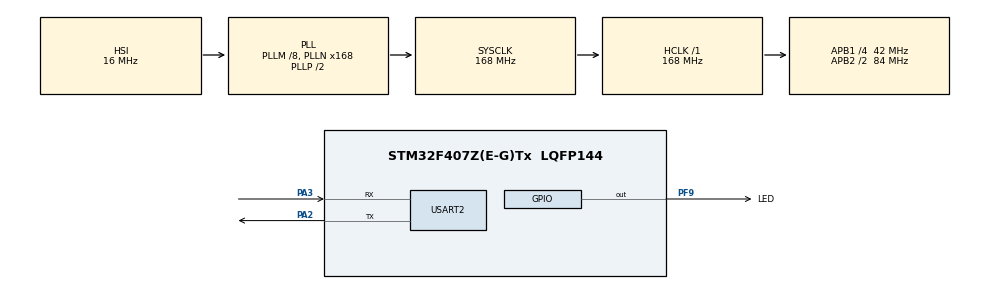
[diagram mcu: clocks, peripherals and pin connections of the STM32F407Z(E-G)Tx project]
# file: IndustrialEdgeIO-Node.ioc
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Dma.Request0=USART2_RX
Dma.Request1=USART2_TX
Dma.USART2_RX.0.Direction=DMA_PERIPH_TO_MEMORY
Dma.USART2_RX.0.FIFOMode=DMA_FIFOMODE_DISABLE
Dma.USART2_RX.0.Instance=DMA1_Stream5
Dma.USART2_RX.0.MemDataAlignment=DMA_MDATAALIGN_BYTE
Dma.USART2_RX.0.MemInc=DMA_MINC_ENABLE
Dma.USART2_RX.0.Mode=DMA_NORMAL
Dma.USART2_RX.0.PeriphDataAlignment=DMA_PDATAALIGN_BYTE
Dma.USART2_RX.0.PeriphInc=DMA_PINC_DISABLE
Dma.USART2_RX.0.Priority=DMA_PRIORITY_LOW
Dma.USART2_TX.1.Direction=DMA_MEMORY_TO_PERIPH
Dma.USART2_TX.1.FIFOMode=DMA_FIFOMODE_DISABLE
Dma.USART2_TX.1.Instance=DMA1_Stream6
Dma.USART2_TX.1.MemDataAlignment=DMA_MDATAALIGN_BYTE
Dma.USART2_TX.1.MemInc=DMA_MINC_ENABLE
Dma.USART2_TX.1.Mode=DMA_NORMAL
Dma.USART2_TX.1.PeriphDataAlignment=DMA_PDATAALIGN_BYTE
Dma.USART2_TX.1.PeriphInc=DMA_PINC_DISABLE
Dma.USART2_TX.1.Priority=DMA_PRIORITY_LOW
FREERTOS.Tasks01=defaultTask,24,128,StartDefaultTask,Default,NULL,Dynamic,NULL,NULL
Mcu.Family=STM32F4
Mcu.Name=STM32F407Z(E-G)Tx
Mcu.Package=LQFP144
NVIC.DMA1_Stream5_IRQn=true\:5\:0\:false\:false\:true\:true\:false\:true\:true
NVIC.DMA1_Stream6_IRQn=true\:5\:0\:false\:false\:true\:true\:false\:true\:true
NVIC.PriorityGroup=NVIC_PRIORITYGROUP_4
NVIC.TIM6_DAC_IRQn=true\:15\:0\:false\:false\:true\:false\:false\:true\:true
NVIC.TimeBase=TIM6_DAC_IRQn
NVIC.TimeBaseIP=TIM6
NVIC.USART2_IRQn=true\:5\:0\:false\:false\:true\:true\:true\:true\:true
PA13.Mode=Serial_Wire
PA13.Signal=SYS_JTMS-SWDIO
PA14.Mode=Serial_Wire
PA14.Signal=SYS_JTCK-SWCLK
PA2.Mode=Asynchronous
PA2.Signal=USART2_TX
PA3.Mode=Asynchronous
PA3.Signal=USART2_RX
PC14-OSC32_IN.Mode=LSE-External-Oscillator
PC14-OSC32_IN.Signal=RCC_OSC32_IN
PC15-OSC32_OUT.Mode=LSE-External-Oscillator
PC15-OSC32_OUT.Signal=RCC_OSC32_OUT
PF9.GPIO_Label=LED
PF9.Signal=GPIO_Output
PH0-OSC_IN.Mode=HSE-External-Oscillator
PH0-OSC_IN.Signal=RCC_OSC_IN
PH1-OSC_OUT.Mode=HSE-External-Oscillator
PH1-OSC_OUT.Signal=RCC_OSC_OUT
ProjectManager.HeapSize=0x200
ProjectManager.StackSize=0x400
ProjectManager.TargetToolchain=MDK-ARM V5.32
RCC.48MHZClocksFreq_Value=84000000
RCC.AHBFreq_Value=168000000
RCC.APB1CLKDivider=RCC_HCLK_DIV4
RCC.APB1Freq_Value=42000000
RCC.APB1TimFreq_Value=84000000
RCC.APB2CLKDivider=RCC_HCLK_DIV2
RCC.APB2Freq_Value=84000000
RCC.APB2TimFreq_Value=168000000
RCC.CortexFreq_Value=168000000
RCC.HCLKFreq_Value=168000000
RCC.HSE_VALUE=25000000
RCC.HSI_VALUE=16000000
RCC.PLLM=8
RCC.PLLN=168
RCC.SYSCLKFreq_VALUE=168000000
RCC.SYSCLKSource=RCC_SYSCLKSOURCE_PLLCLK
RCC.VCOOutputFreq_Value=336000000
USART2.VirtualMode=VM_ASYNC
VP_FREERTOS_VS_CMSIS_V2.Mode=CMSIS_V2
VP_SYS_VS_tim6.Mode=TIM6
board=custom

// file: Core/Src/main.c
/* USER CODE BEGIN Header */
/**
 ******************************************************************************
 * @file           : main.c
 * @brief          : Main program body
 ******************************************************************************
 * @attention
 *
 * Copyright (c) 2026 STMicroelectronics.
 * All rights reserved.
 *
 * This software is licensed under terms that can be found in the LICENSE file
 * in the root directory of this software component.
 * If no LICENSE file comes with this software, it is provided AS-IS.
 *
 ******************************************************************************
 */
/* USER CODE END Header */
#include "main.h"
#include "cmsis_os.h"
#include "dma.h"
#include "gpio.h"
#include "usart.h"

/* USER CODE BEGIN Includes */
#include "CRC.h"
#include "modbus.h"
#include <stdio.h>
#include <string.h>
/* USER CODE END Includes */

/* USER CODE BEGIN PV */
volatile uint8_t Modbus_Frame_Flag = 0;
/* USER CODE END PV */

void SystemClock_Config(void);
void MX_FREERTOS_Init(void);

/* USER CODE BEGIN 0 */
void HAL_UARTEx_RxEventCallback(UART_HandleTypeDef *huart, uint16_t Size) {
  if (huart->Instance == USART2) {
    if (Size > 0) {
      Modbus_RX_Length = Size;
    }
  }
}
/* USER CODE END 0 */

int main(void) {

  /* MCU Configuration--------------------------------------------------------*/

  /* Reset of all peripherals, Initializes the Flash interface and the Systick.
   */
  HAL_Init();

  /* Configure the system clock */
  SystemClock_Config();

  /* Initialize all configured peripherals */
  MX_GPIO_Init();
  MX_DMA_Init();
  MX_USART2_UART_Init();

  /* Init scheduler */
  osKernelInitialize(); /* Call init function for freertos objects (in
                           cmsis_os2.c) */
  MX_FREERTOS_Init();

  /* Start scheduler */
  osKernelStart();

  /* We should never get here as control is now taken by the scheduler */

  /* Infinite loop */
  while (1) {

  }
}

void SystemClock_Config(void) {
  RCC_OscInitTypeDef RCC_OscInitStruct = {0};
  RCC_ClkInitTypeDef RCC_ClkInitStruct = {0};

  /** Configure the main internal regulator output voltage
   */
  __HAL_RCC_PWR_CLK_ENABLE();
  __HAL_PWR_VOLTAGESCALING_CONFIG(PWR_REGULATOR_VOLTAGE_SCALE1);

  /** Initializes the RCC Oscillators according to the specified parameters
   * in the RCC_OscInitTypeDef structure.
   */
  RCC_OscInitStruct.OscillatorType = RCC_OSCILLATORTYPE_HSI;
  RCC_OscInitStruct.HSIState = RCC_HSI_ON;
  RCC_OscInitStruct.HSICalibrationValue = RCC_HSICALIBRATION_DEFAULT;
  RCC_OscInitStruct.PLL.PLLState = RCC_PLL_ON;
  RCC_OscInitStruct.PLL.PLLSource = RCC_PLLSOURCE_HSI;
  RCC_OscInitStruct.PLL.PLLM = 8;
  RCC_OscInitStruct.PLL.PLLN = 168;
  RCC_OscInitStruct.PLL.PLLP = RCC_PLLP_DIV2;
  RCC_OscInitStruct.PLL.PLLQ = 4;
  if (HAL_RCC_OscConfig(&RCC_OscInitStruct) != HAL_OK) {
    Error_Handler();
  }

  /** Initializes the CPU, AHB and APB buses clocks
   */
  RCC_ClkInitStruct.ClockType = RCC_CLOCKTYPE_HCLK | RCC_CLOCKTYPE_SYSCLK |
                                RCC_CLOCKTYPE_PCLK1 | RCC_CLOCKTYPE_PCLK2;
  RCC_ClkInitStruct.SYSCLKSource = RCC_SYSCLKSOURCE_PLLCLK;
  RCC_ClkInitStruct.AHBCLKDivider = RCC_SYSCLK_DIV1;
  RCC_ClkInitStruct.APB1CLKDivider = RCC_HCLK_DIV4;
  RCC_ClkInitStruct.APB2CLKDivider = RCC_HCLK_DIV2;

  if (HAL_RCC_ClockConfig(&RCC_ClkInitStruct, FLASH_LATENCY_5) != HAL_OK) {
    Error_Handler();
  }
}

void HAL_TIM_PeriodElapsedCallback(TIM_HandleTypeDef *htim) {
  if (htim->Instance == TIM6) {
    HAL_IncTick();
  }
}

void Error_Handler(void) {
  __disable_irq();
  while (1) {
  }
}
#ifdef USE_FULL_ASSERT
/**
 * @brief  Reports the name of the source file and the source line number
 *         where the assert_param error has occurred.
 * @param  file: pointer to the source file name
 * @param  line: assert_param error line source number
 * @retval None
 */
void assert_failed(uint8_t *file, uint32_t line) {
  /* USER CODE BEGIN 6 */
  /* User can add his own implementation to report the file name and line
     number, ex: printf("Wrong parameters value: file %s on line %d\r\n", file,
     line) */
  /* USER CODE END 6 */
}
#endif /* USE_FULL_ASSERT */

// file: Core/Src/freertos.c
/* USER CODE BEGIN Header */
/**
 ******************************************************************************
 * File Name          : freertos.c
 * Description        : Code for freertos applications
 ******************************************************************************
 * @attention
 *
 * Copyright (c) 2026 STMicroelectronics.
 * All rights reserved.
 *
 * This software is licensed under terms that can be found in the LICENSE file
 * in the root directory of this software component.
 * If no LICENSE file comes with this software, it is provided AS-IS.
 *
 ******************************************************************************
 */
/* USER CODE END Header */

#include "FreeRTOS.h"
#include "cmsis_os.h"
#include "main.h"
#include "task.h"

/* USER CODE BEGIN Includes */
#include "modbus.h"
#include "usart.h"
#include <string.h>
/* USER CODE END Includes */

/* Definitions for defaultTask */
osThreadId_t defaultTaskHandle;
const osThreadAttr_t defaultTask_attributes = {
    .name = "defaultTask",
    .stack_size = 128 * 4,
    .priority = (osPriority_t)osPriorityNormal,
};

void StartDefaultTask(void *argument);

void MX_FREERTOS_Init(void); /* (MISRA C 2004 rule 8.1) */

void MX_FREERTOS_Init(void) {

  /* Create the thread(s) */
  /* creation of defaultTask */
  defaultTaskHandle =
      osThreadNew(StartDefaultTask, NULL, &defaultTask_attributes);

}

void StartDefaultTask(void *argument) {
  /* USER CODE BEGIN StartDefaultTask */
  Modbus_Register_Init();

  HAL_UARTEx_ReceiveToIdle_DMA(&huart2, Modbus_RX_Buffer,
                               sizeof(Modbus_RX_Buffer));
  __HAL_DMA_DISABLE_IT(huart2.hdmarx, DMA_IT_HT);

  for (;;) {
    osDelay(5);

    if (Modbus_RX_Length > 0) {
      if (Modbus_Server() == 1)
        Modbus_Register[REG_COMM_STATE] = 0;
      else
        Modbus_Register[REG_COMM_STATE] = 1;

      memset(Modbus_RX_Buffer, 0, sizeof(Modbus_RX_Buffer));
      Modbus_RX_Length = 0;

      HAL_UARTEx_ReceiveToIdle_DMA(&huart2, Modbus_RX_Buffer,
                                   sizeof(Modbus_RX_Buffer));
      __HAL_DMA_DISABLE_IT(huart2.hdmarx, DMA_IT_HT);
    }
  }
}
/* USER CODE END StartDefaultTask */
